/****************************************************************************
** File : LIN_LDF.ldf
** Description : LIN Description file for the defined LIN cluster
*****************************************************************************/

LIN_description_file;
LIN_protocol_version = "2.1";
LIN_language_version = "2.1";
LIN_speed = 19.2 kbps;
Channel_name = "LIN_Configuration1";

Nodes {
  Master: LINMaster, 5 ms, 0.1 ms ;
  Slaves: Motor ;
}

Signals {
  RefSpeed: 16, 0, LINMaster, Motor ;
  ActSpeed: 16, 0, Motor, LINMaster ;
  Temperature: 8, 0, Motor, LINMaster ;
  Status: 8, 0, Motor, LINMaster ;
}

Frames {
  MotorCtrl: 42, LINMaster, 8 {
    RefSpeed, 0 ;
  }
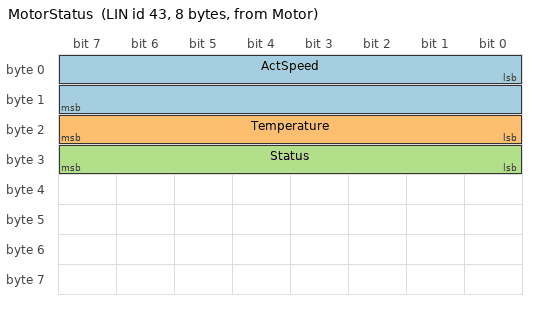
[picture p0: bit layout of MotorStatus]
  MotorStatus: 43, Motor, 8 {
    ActSpeed, 0 ;
    Temperature, 16 ;
    Status, 24 ;
  }
}

Node_attributes {
  Motor{
    LIN_protocol = "2.1" ;
    configured_NAD = 0x1 ;
    initial_NAD = 0x1 ;
    product_id = 0x1234, 0x5678, 0 ;
    P2_min = 50 ms ;
    ST_min = 0 ms ;
    N_As_timeout = 1000 ms ;
    N_Cr_timeout = 1000 ms ;
    configurable_frames {
      MotorCtrl ;
      MotorStatus ;
    }
  }
}

Schedule_tables {
 Run {
    MotorCtrl delay 10 ms ;
    MotorStatus delay 10 ms ;
  }
}
